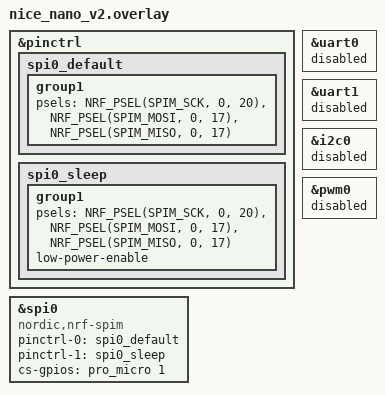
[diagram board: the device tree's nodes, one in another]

&pinctrl {
    spi0_default: spi0_default {
        group1 {
            psels = <NRF_PSEL(SPIM_SCK,  0, 20)>, // SCLK P0.20
                    <NRF_PSEL(SPIM_MOSI, 0, 17)>, // MOSI P0.17
                    <NRF_PSEL(SPIM_MISO, 0, 17)>; // MISO P0.06
        };
    };

    spi0_sleep: spi0_sleep {
        group1 {
            psels = <NRF_PSEL(SPIM_SCK,  0, 20)>, // SCLK P0.20
                    <NRF_PSEL(SPIM_MOSI, 0, 17)>, // MOSI/SDIO P0.17
                    <NRF_PSEL(SPIM_MISO, 0, 17)>; // MISO P0.06
            low-power-enable;
        };
    };

};

&uart0 {
	status = "disabled";
};

&uart1 {
	status = "disabled";
};

&i2c0 {
	status = "disabled";
};

&pwm0 {
	status = "disabled";
};


#include <zephyr/dt-bindings/input/input-event-codes.h>
#include <behaviors/input_gestures_accel.dtsi>
#include <behaviors.dtsi>
#include <dt-bindings/zmk/keys.h>


nice_view_spi: &spi0 {
    compatible = "nordic,nrf-spim";
    pinctrl-0 = <&spi0_default>;
    pinctrl-1 = <&spi0_sleep>;
    pinctrl-names = "default", "sleep";
    cs-gpios = <&pro_micro 1 GPIO_ACTIVE_HIGH>;
};



